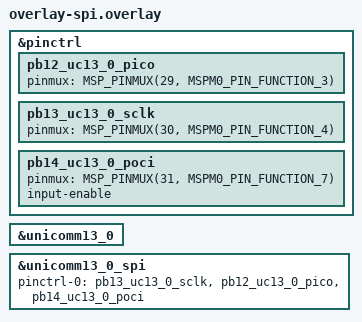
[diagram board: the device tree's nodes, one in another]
/*
 * LP-MSPM33C321A devicetree additions for MicroPython's machine.SPI.
 * SPI on UNICOMM13_0: SCLK PB13, PICO PB12, POCI PB14 (BoosterPack header pins 9, 10 and 14). No chip select pin.
 * Used as: -DEXTRA_DTC_OVERLAY_FILE=<this file>
 */
&pinctrl {
	pb12_uc13_0_pico: pb12_uc13_0_pico {
		pinmux = <MSP_PINMUX(29, MSPM0_PIN_FUNCTION_3)>;
	};

	pb13_uc13_0_sclk: pb13_uc13_0_sclk {
		pinmux = <MSP_PINMUX(30, MSPM0_PIN_FUNCTION_4)>;
	};

	pb14_uc13_0_poci: pb14_uc13_0_poci {
		pinmux = <MSP_PINMUX(31, MSPM0_PIN_FUNCTION_7)>;
		input-enable;
	};
};

&unicomm13_0 {
	status = "okay";
};

&unicomm13_0_spi {
	status = "okay";
	pinctrl-0 = <&pb13_uc13_0_sclk &pb12_uc13_0_pico &pb14_uc13_0_poci>;
	pinctrl-names = "default";
};
